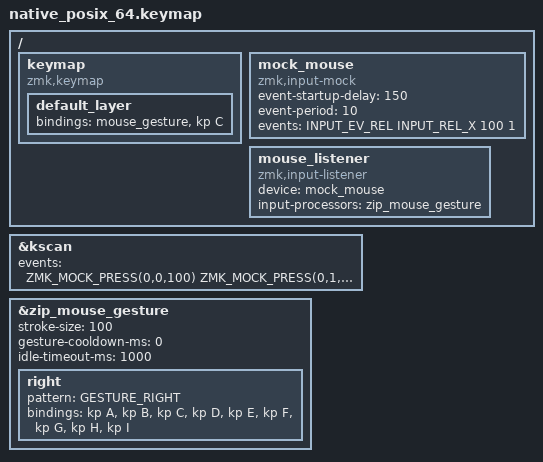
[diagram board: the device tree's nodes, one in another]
#include "../../behavior_keymap.dtsi"

/ {
    keymap {
        compatible = "zmk,keymap";
        default_layer {
            bindings = <&mouse_gesture &kp C>;
        };
    };

    mock_mouse: mock_mouse {
        compatible = "zmk,input-mock";
        event-startup-delay = <150>;
        event-period = <10>;
        events = <
            INPUT_EV_REL INPUT_REL_X 100 1
        >;
    };

    mouse_listener: mouse_listener {
        compatible = "zmk,input-listener";
        device = <&mock_mouse>;
        input-processors = <&zip_mouse_gesture>;
    };
};

&kscan {
    events = <
        ZMK_MOCK_PRESS(0,0,100)
        ZMK_MOCK_PRESS(0,1,10)
        ZMK_MOCK_RELEASE(0,1,500)
        ZMK_MOCK_RELEASE(0,0,3000)
    >;
};

&zip_mouse_gesture {
    stroke-size = <100>;
    gesture-cooldown-ms = <0>;
    idle-timeout-ms = <1000>;

    right {
        pattern = <GESTURE_RIGHT>;
        bindings = <&kp A>, <&kp B>, <&kp C>, <&kp D>, <&kp E>, <&kp F>, <&kp G>, <&kp H>, <&kp I>;
    };
};
